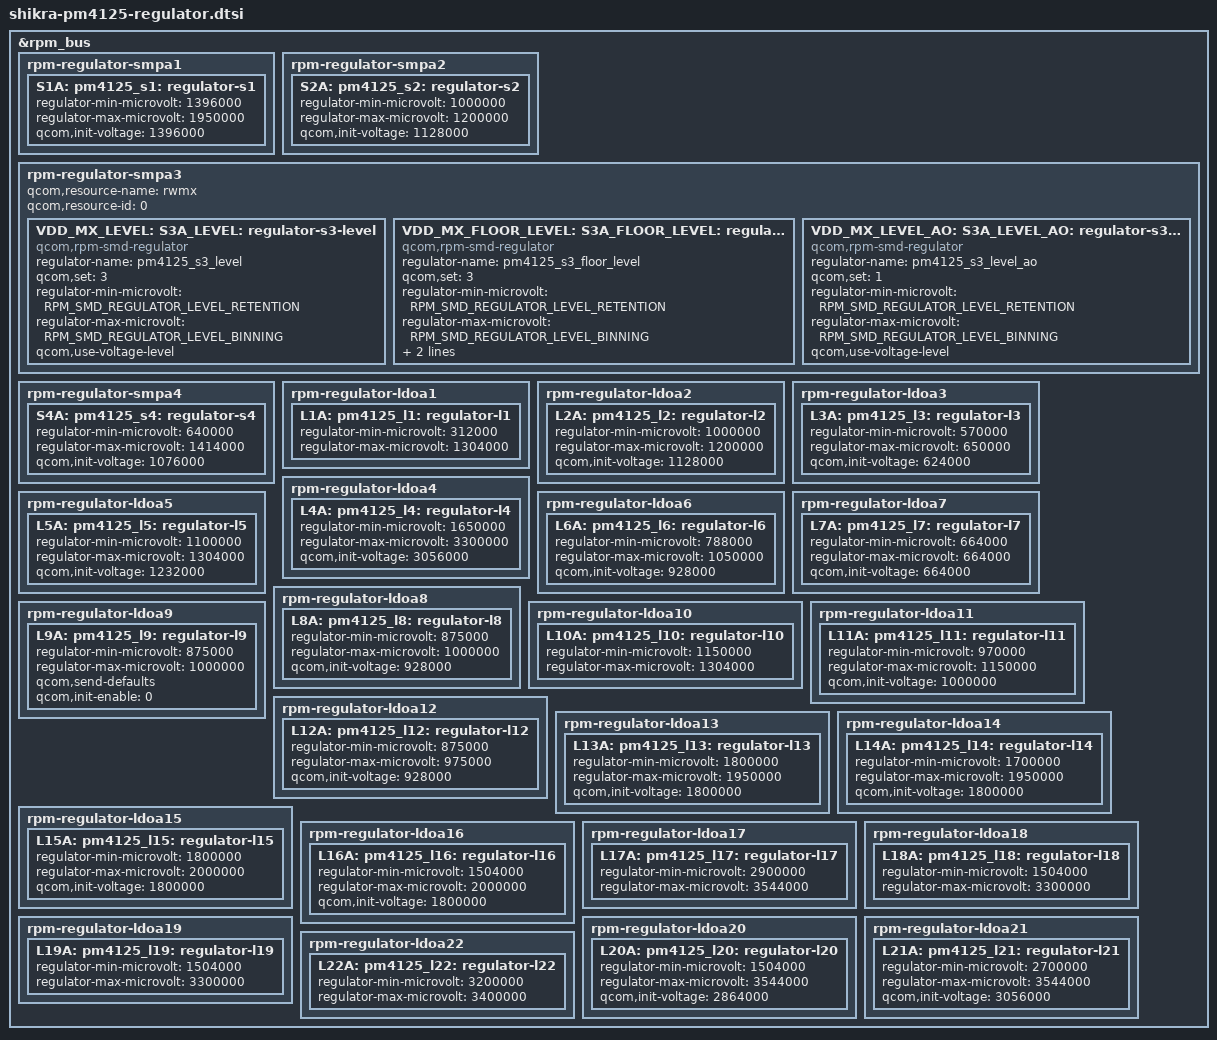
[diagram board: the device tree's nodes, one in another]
// SPDX-License-Identifier: BSD-3-Clause
/*
 * Copyright (c) Qualcomm Technologies, Inc. and/or its subsidiaries.
 */

#include <dt-bindings/regulator/qcom,rpm-smd-regulator.h>
#include "pm4125-rpm-regulator.dtsi"

&rpm_bus {
	rpm-regulator-smpa1 {
		status = "okay";
		S1A: pm4125_s1: regulator-s1 {
			regulator-min-microvolt = <1396000>;
			regulator-max-microvolt = <1950000>;
			qcom,init-voltage = <1396000>;
			status = "okay";
		};
	};

	rpm-regulator-smpa2 {
		status = "okay";
		S2A: pm4125_s2: regulator-s2 {
			regulator-min-microvolt = <1000000>;
			regulator-max-microvolt = <1200000>;
			qcom,init-voltage = <1128000>;
			status = "okay";
		};
	};

	/* PM4125 S3A - VDD_MX supply */
	rpm-regulator-smpa3 {
		status = "okay";
		qcom,resource-name = "rwmx";
		qcom,resource-id = <0>;

		VDD_MX_LEVEL:
		S3A_LEVEL: pm4125_s3_level: regulator-s3-level {
			compatible = "qcom,rpm-smd-regulator";
			regulator-name = "pm4125_s3_level";
			qcom,set = <3>;
			regulator-min-microvolt =
			<RPM_SMD_REGULATOR_LEVEL_RETENTION>;
			regulator-max-microvolt =
			<RPM_SMD_REGULATOR_LEVEL_BINNING>;
			qcom,use-voltage-level;
		};

		VDD_MX_FLOOR_LEVEL:
		S3A_FLOOR_LEVEL:
		pm4125_s3_floor_level: regulator-s3-floor-level {
			compatible = "qcom,rpm-smd-regulator";
			regulator-name = "pm4125_s3_floor_level";
			qcom,set = <3>;
			regulator-min-microvolt =
			<RPM_SMD_REGULATOR_LEVEL_RETENTION>;
			regulator-max-microvolt =
			<RPM_SMD_REGULATOR_LEVEL_BINNING>;
			qcom,use-voltage-floor-level;
			qcom,always-send-voltage;
		};

		VDD_MX_LEVEL_AO:
		S3A_LEVEL_AO: pm4125_s3_level_ao: regulator-s3-level-ao {
			compatible = "qcom,rpm-smd-regulator";
			regulator-name = "pm4125_s3_level_ao";
			qcom,set = <1>;
			regulator-min-microvolt =
			<RPM_SMD_REGULATOR_LEVEL_RETENTION>;
			regulator-max-microvolt =
			<RPM_SMD_REGULATOR_LEVEL_BINNING>;
			qcom,use-voltage-level;
		};
	};

	rpm-regulator-smpa4 {
		status = "okay";
		S4A: pm4125_s4: regulator-s4 {
			regulator-min-microvolt = <640000>;
			regulator-max-microvolt = <1414000>;
			qcom,init-voltage = <1076000>;
			status = "okay";
		};
	};

	rpm-regulator-ldoa1 {
		status = "okay";
		L1A: pm4125_l1: regulator-l1 {
			regulator-min-microvolt = <312000>;
			regulator-max-microvolt = <1304000>;
			status = "okay";
		};
	};

	rpm-regulator-ldoa2 {
		status = "okay";
		L2A: pm4125_l2: regulator-l2 {
			regulator-min-microvolt = <1000000>;
			regulator-max-microvolt = <1200000>;
			qcom,init-voltage = <1128000>;
			status = "okay";
		};
	};

	rpm-regulator-ldoa3 {
		status = "okay";
		L3A: pm4125_l3: regulator-l3 {
			regulator-min-microvolt = <570000>;
			regulator-max-microvolt = <650000>;
			qcom,init-voltage = <624000>;
			status = "okay";
		};
	};

	rpm-regulator-ldoa4 {
		status = "okay";
		L4A: pm4125_l4: regulator-l4 {
			regulator-min-microvolt = <1650000>;
			regulator-max-microvolt = <3300000>;
			qcom,init-voltage = <3056000>;
			status = "okay";
		};
	};

	rpm-regulator-ldoa5 {
		status = "okay";
		L5A: pm4125_l5: regulator-l5 {
			regulator-min-microvolt = <1100000>;
			regulator-max-microvolt = <1304000>;
			qcom,init-voltage = <1232000>;
			status = "okay";
		};
	};

	rpm-regulator-ldoa6 {
		status = "okay";
		L6A: pm4125_l6: regulator-l6 {
			regulator-min-microvolt = <788000>;
			regulator-max-microvolt = <1050000>;
			qcom,init-voltage = <928000>;
			status = "okay";
		};
	};

	rpm-regulator-ldoa7 {
		status = "okay";
		L7A: pm4125_l7: regulator-l7 {
			regulator-min-microvolt = <664000>;
			regulator-max-microvolt = <664000>;
			qcom,init-voltage = <664000>;
			status = "okay";
		};
	};

	rpm-regulator-ldoa8 {
		status = "okay";
		L8A: pm4125_l8: regulator-l8 {
			regulator-min-microvolt = <875000>;
			regulator-max-microvolt = <1000000>;
			qcom,init-voltage = <928000>;
			status = "okay";
		};
	};

	rpm-regulator-ldoa9 {
		status = "okay";
		L9A: pm4125_l9: regulator-l9 {
			regulator-min-microvolt = <875000>;
			regulator-max-microvolt = <1000000>;
			qcom,send-defaults;
			qcom,init-enable = <0>;
			status = "okay";
		};
	};

	rpm-regulator-ldoa10 {
		status = "okay";
		L10A: pm4125_l10: regulator-l10 {
			regulator-min-microvolt = <1150000>;
			regulator-max-microvolt = <1304000>;
			status = "okay";
		};
	};

	rpm-regulator-ldoa11 {
		status = "okay";
		L11A: pm4125_l11: regulator-l11 {
			regulator-min-microvolt = <970000>;
			regulator-max-microvolt = <1150000>;
			qcom,init-voltage = <1000000>;
			status = "okay";
		};
	};

	rpm-regulator-ldoa12 {
		status = "okay";
		L12A: pm4125_l12: regulator-l12 {
			regulator-min-microvolt = <875000>;
			regulator-max-microvolt = <975000>;
			qcom,init-voltage = <928000>;
			status = "okay";
		};
	};

	rpm-regulator-ldoa13 {
		status = "okay";
		L13A: pm4125_l13: regulator-l13 {
			regulator-min-microvolt = <1800000>;
			regulator-max-microvolt = <1950000>;
			qcom,init-voltage = <1800000>;
			status = "okay";
		};
	};

	rpm-regulator-ldoa14 {
		status = "okay";
		L14A: pm4125_l14: regulator-l14 {
			regulator-min-microvolt = <1700000>;
			regulator-max-microvolt = <1950000>;
			qcom,init-voltage = <1800000>;
			status = "okay";
		};
	};

	rpm-regulator-ldoa15 {
		status = "okay";
		L15A: pm4125_l15: regulator-l15 {
			regulator-min-microvolt = <1800000>;
			regulator-max-microvolt = <2000000>;
			qcom,init-voltage = <1800000>;
			status = "okay";
		};
	};

	rpm-regulator-ldoa16 {
		status = "okay";
		L16A: pm4125_l16: regulator-l16 {
			regulator-min-microvolt = <1504000>;
			regulator-max-microvolt = <2000000>;
			qcom,init-voltage = <1800000>;
			status = "okay";
		};
	};

	rpm-regulator-ldoa17 {
		status = "okay";
		L17A: pm4125_l17: regulator-l17 {
			regulator-min-microvolt = <2900000>;
			regulator-max-microvolt = <3544000>;
			status = "okay";
		};
	};

	rpm-regulator-ldoa18 {
		status = "okay";
		L18A: pm4125_l18: regulator-l18 {
			regulator-min-microvolt = <1504000>;
			regulator-max-microvolt = <3300000>;
			status = "okay";
		};
	};

	rpm-regulator-ldoa19 {
		status = "okay";
		L19A: pm4125_l19: regulator-l19 {
			regulator-min-microvolt = <1504000>;
			regulator-max-microvolt = <3300000>;
			status = "okay";
		};
	};

	rpm-regulator-ldoa20 {
		status = "okay";
		L20A: pm4125_l20: regulator-l20 {
			regulator-min-microvolt = <1504000>;
			regulator-max-microvolt = <3544000>;
			qcom,init-voltage = <2864000>;
			status = "okay";
		};
	};

	rpm-regulator-ldoa21 {
		status = "okay";
		L21A: pm4125_l21: regulator-l21 {
			regulator-min-microvolt = <2700000>;
			regulator-max-microvolt = <3544000>;
			qcom,init-voltage = <3056000>;
			status = "okay";
		};
	};

	rpm-regulator-ldoa22 {
		status = "okay";
		L22A: pm4125_l22: regulator-l22 {
			regulator-min-microvolt = <3200000>;
			regulator-max-microvolt = <3400000>;
			status = "okay";
		};
	};
};
